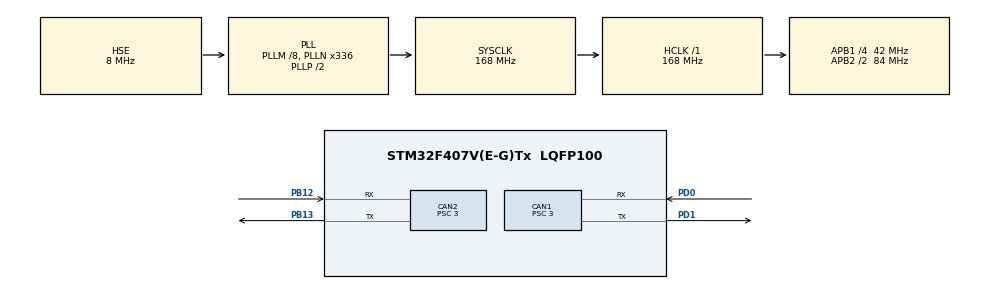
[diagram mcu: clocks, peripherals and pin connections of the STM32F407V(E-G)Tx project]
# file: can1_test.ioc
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CAN1.BS1=CAN_BS1_9TQ
CAN1.BS2=CAN_BS2_4TQ
CAN1.CalculateBaudRate=1000000
CAN1.CalculateTimeBit=999.99
CAN1.CalculateTimeQuantum=71.42857142857143
CAN1.Prescaler=3
CAN1.TXFP=ENABLE
CAN2.BS1=CAN_BS1_9TQ
CAN2.BS2=CAN_BS2_4TQ
CAN2.CalculateBaudRate=1000000
CAN2.CalculateTimeBit=999.99
CAN2.CalculateTimeQuantum=71.42857142857143
CAN2.Prescaler=3
CAN2.TXFP=ENABLE
FREERTOS.BinarySemaphores01=myBinarySem01,Dynamic,NULL;myBinarySem02,Dynamic,NULL
FREERTOS.Tasks01=defaultTask,0,128,StartDefaultTask,Default,NULL,Dynamic,NULL,NULL;pid_Task,0,128,PID_Task,Default,NULL,Dynamic,NULL,NULL
FREERTOS.Timers01=myTimer01,Callback01,osTimerPeriodic,Default,NULL,Dynamic,NULL
FREERTOS.configTIMER_TASK_PRIORITY=3
FREERTOS.configUSE_TIMERS=1
Mcu.Family=STM32F4
Mcu.Name=STM32F407V(E-G)Tx
Mcu.Package=LQFP100
NVIC.CAN1_RX0_IRQn=true\:5\:0\:false\:false\:true\:true\:true\:true
NVIC.CAN1_TX_IRQn=true\:5\:0\:false\:false\:true\:true\:true\:true
NVIC.CAN2_RX0_IRQn=true\:5\:0\:false\:false\:true\:true\:true\:true
NVIC.CAN2_TX_IRQn=true\:5\:0\:false\:false\:true\:true\:true\:true
NVIC.PriorityGroup=NVIC_PRIORITYGROUP_4
NVIC.TIM6_DAC_IRQn=true\:15\:0\:false\:false\:true\:false\:false\:true
NVIC.TimeBase=TIM6_DAC_IRQn
NVIC.TimeBaseIP=TIM6
NVIC.WWDG_IRQn=true\:5\:0\:false\:false\:true\:true\:true\:true
PA13.Mode=Serial_Wire
PA13.Signal=SYS_JTMS-SWDIO
PA14.Mode=Serial_Wire
PA14.Signal=SYS_JTCK-SWCLK
PB12.Mode=CAN_Activate
PB12.Signal=CAN2_RX
PB13.Mode=CAN_Activate
PB13.Signal=CAN2_TX
PD0.Mode=CAN_Activate
PD0.Signal=CAN1_RX
PD1.Mode=CAN_Activate
PD1.Signal=CAN1_TX
PH0-OSC_IN.Mode=HSE-External-Oscillator
PH0-OSC_IN.Signal=RCC_OSC_IN
PH1-OSC_OUT.Mode=HSE-External-Oscillator
PH1-OSC_OUT.Signal=RCC_OSC_OUT
ProjectManager.HeapSize=0x200
ProjectManager.StackSize=0x400
ProjectManager.TargetToolchain=MDK-ARM V5.32
RCC.48MHZClocksFreq_Value=84000000
RCC.AHBFreq_Value=168000000
RCC.APB1CLKDivider=RCC_HCLK_DIV4
RCC.APB1Freq_Value=42000000
RCC.APB1TimFreq_Value=84000000
RCC.APB2CLKDivider=RCC_HCLK_DIV2
RCC.APB2Freq_Value=84000000
RCC.APB2TimFreq_Value=168000000
RCC.CortexFreq_Value=168000000
RCC.HCLKFreq_Value=168000000
RCC.HSE_VALUE=8000000
RCC.HSI_VALUE=16000000
RCC.LSE_VALUE=32768
RCC.PLLM=8
RCC.PLLN=336
RCC.PLLSourceVirtual=RCC_PLLSOURCE_HSE
RCC.SYSCLKFreq_VALUE=168000000
RCC.SYSCLKSource=RCC_SYSCLKSOURCE_PLLCLK
RCC.VCOOutputFreq_Value=336000000
VP_FREERTOS_VS_CMSIS_V1.Mode=CMSIS_V1
VP_SYS_VS_tim6.Mode=TIM6
VP_WWDG_VS_WWDG.Mode=WWDG_Activate
WWDG.Counter=127
WWDG.EWIMode=WWDG_EWI_ENABLE
WWDG.Prescaler=WWDG_PRESCALER_2
board=custom

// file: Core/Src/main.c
/* USER CODE BEGIN Header */
/**
  ******************************************************************************
  * @file           : main.c
  * @brief          : Main program body
  ******************************************************************************
  * @attention
  *
  * <h2><center>&copy; Copyright (c) 2021 STMicroelectronics.
  * All rights reserved.</center></h2>
  *
  * This software component is licensed by ST under BSD 3-Clause license,
  * the "License"; You may not use this file except in compliance with the
  * License. You may obtain a copy of the License at:
  *                        opensource.org/licenses/BSD-3-Clause
  *
  ******************************************************************************
  */
/* USER CODE END Header */
#include "main.h"
#include "cmsis_os.h"
#include "can.h"
#include "wwdg.h"
#include "gpio.h"

/* USER CODE BEGIN Includes */
#include "global_variate.h"
/* USER CODE END Includes */

void SystemClock_Config(void);
void MX_FREERTOS_Init(void);

int main(void)
{

  /* MCU Configuration--------------------------------------------------------*/

  /* Reset of all peripherals, Initializes the Flash interface and the Systick. */
  HAL_Init();

  /* Configure the system clock */
  SystemClock_Config();

  /* Initialize all configured peripherals */
  MX_GPIO_Init();
  MX_CAN1_Init();
  MX_CAN2_Init();
  MX_WWDG_Init();

  /* Call init function for freertos objects (in freertos.c) */
  MX_FREERTOS_Init();
  /* Start scheduler */
  osKernelStart();

  /* We should never get here as control is now taken by the scheduler */
  /* Infinite loop */
  while (1)
  {

  }
}

void SystemClock_Config(void)
{
  RCC_OscInitTypeDef RCC_OscInitStruct = {0};
  RCC_ClkInitTypeDef RCC_ClkInitStruct = {0};

  /** Configure the main internal regulator output voltage
  */
  __HAL_RCC_PWR_CLK_ENABLE();
  __HAL_PWR_VOLTAGESCALING_CONFIG(PWR_REGULATOR_VOLTAGE_SCALE1);
  /** Initializes the RCC Oscillators according to the specified parameters
  * in the RCC_OscInitTypeDef structure.
  */
  RCC_OscInitStruct.OscillatorType = RCC_OSCILLATORTYPE_HSE;
  RCC_OscInitStruct.HSEState = RCC_HSE_ON;
  RCC_OscInitStruct.PLL.PLLState = RCC_PLL_ON;
  RCC_OscInitStruct.PLL.PLLSource = RCC_PLLSOURCE_HSE;
  RCC_OscInitStruct.PLL.PLLM = 8;
  RCC_OscInitStruct.PLL.PLLN = 336;
  RCC_OscInitStruct.PLL.PLLP = RCC_PLLP_DIV2;
  RCC_OscInitStruct.PLL.PLLQ = 4;
  if (HAL_RCC_OscConfig(&RCC_OscInitStruct) != HAL_OK)
  {
    Error_Handler();
  }
  /** Initializes the CPU, AHB and APB buses clocks
  */
  RCC_ClkInitStruct.ClockType = RCC_CLOCKTYPE_HCLK|RCC_CLOCKTYPE_SYSCLK
                              |RCC_CLOCKTYPE_PCLK1|RCC_CLOCKTYPE_PCLK2;
  RCC_ClkInitStruct.SYSCLKSource = RCC_SYSCLKSOURCE_PLLCLK;
  RCC_ClkInitStruct.AHBCLKDivider = RCC_SYSCLK_DIV1;
  RCC_ClkInitStruct.APB1CLKDivider = RCC_HCLK_DIV4;
  RCC_ClkInitStruct.APB2CLKDivider = RCC_HCLK_DIV2;

  if (HAL_RCC_ClockConfig(&RCC_ClkInitStruct, FLASH_LATENCY_5) != HAL_OK)
  {
    Error_Handler();
  }
}

void HAL_TIM_PeriodElapsedCallback(TIM_HandleTypeDef *htim)
{
  if (htim->Instance == TIM6) {
    HAL_IncTick();
  }
}

void Error_Handler(void)
{
  __disable_irq();
  while (1)
  {
  }
}

/************************ (C) COPYRIGHT STMicroelectronics *****END OF FILE****/

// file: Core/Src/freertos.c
/* USER CODE BEGIN Header */
/**
  ******************************************************************************
  * File Name          : freertos.c
  * Description        : Code for freertos applications
  ******************************************************************************
  * @attention
  *
  * <h2><center>&copy; Copyright (c) 2021 STMicroelectronics.
  * All rights reserved.</center></h2>
  *
  * This software component is licensed by ST under Ultimate Liberty license
  * SLA0044, the "License"; You may not use this file except in compliance with
  * the License. You may obtain a copy of the License at:
  *                             www.st.com/SLA0044
  *
  ******************************************************************************
  */
/* USER CODE END Header */

#include "FreeRTOS.h"
#include "task.h"
#include "main.h"
#include "cmsis_os.h"

/* USER CODE BEGIN Includes */

#include "can.h"
#include "PID.h"
#include "global_variate.h"
#include "motor_control.h"

/* USER CODE END Includes */

/* USER CODE BEGIN PD */

//extern float target_pitch_angle;
//extern float target_yaw_angle;

/* USER CODE END PD */

osThreadId defaultTaskHandle;
osThreadId pid_TaskHandle;
osTimerId myTimer01Handle;
osSemaphoreId myBinarySem01Handle;
osSemaphoreId myBinarySem02Handle;

void StartDefaultTask(void const * argument);
void PID_Task(void const * argument);
void Callback01(void const * argument);

void MX_FREERTOS_Init(void); /* (MISRA C 2004 rule 8.1) */

/* GetIdleTaskMemory prototype (linked to static allocation support) */
void vApplicationGetIdleTaskMemory( StaticTask_t **ppxIdleTaskTCBBuffer, StackType_t **ppxIdleTaskStackBuffer, uint32_t *pulIdleTaskStackSize );

/* GetTimerTaskMemory prototype (linked to static allocation support) */
void vApplicationGetTimerTaskMemory( StaticTask_t **ppxTimerTaskTCBBuffer, StackType_t **ppxTimerTaskStackBuffer, uint32_t *pulTimerTaskStackSize );

/* USER CODE BEGIN GET_IDLE_TASK_MEMORY */
static StaticTask_t xIdleTaskTCBBuffer;
static StackType_t xIdleStack[configMINIMAL_STACK_SIZE];

void vApplicationGetIdleTaskMemory( StaticTask_t **ppxIdleTaskTCBBuffer, StackType_t **ppxIdleTaskStackBuffer, uint32_t *pulIdleTaskStackSize )
{
  *ppxIdleTaskTCBBuffer = &xIdleTaskTCBBuffer;
  *ppxIdleTaskStackBuffer = &xIdleStack[0];
  *pulIdleTaskStackSize = configMINIMAL_STACK_SIZE;
  /* place for user code */
}
/* USER CODE END GET_IDLE_TASK_MEMORY */

/* USER CODE BEGIN GET_TIMER_TASK_MEMORY */
static StaticTask_t xTimerTaskTCBBuffer;
static StackType_t xTimerStack[configTIMER_TASK_STACK_DEPTH];

void vApplicationGetTimerTaskMemory( StaticTask_t **ppxTimerTaskTCBBuffer, StackType_t **ppxTimerTaskStackBuffer, uint32_t *pulTimerTaskStackSize )
{
  *ppxTimerTaskTCBBuffer = &xTimerTaskTCBBuffer;
  *ppxTimerTaskStackBuffer = &xTimerStack[0];
  *pulTimerTaskStackSize = configTIMER_TASK_STACK_DEPTH;
  /* place for user code */
}
/* USER CODE END GET_TIMER_TASK_MEMORY */

void MX_FREERTOS_Init(void) {

  /* Create the semaphores(s) */
  /* definition and creation of myBinarySem01 */
  osSemaphoreDef(myBinarySem01);
  myBinarySem01Handle = osSemaphoreCreate(osSemaphore(myBinarySem01), 1);

  /* definition and creation of myBinarySem02 */
  osSemaphoreDef(myBinarySem02);
  myBinarySem02Handle = osSemaphoreCreate(osSemaphore(myBinarySem02), 1);

  /* Create the timer(s) */
  /* definition and creation of myTimer01 */
  osTimerDef(myTimer01, Callback01);
  myTimer01Handle = osTimerCreate(osTimer(myTimer01), osTimerPeriodic, NULL);

  /* Create the thread(s) */
  /* definition and creation of defaultTask */
  osThreadDef(defaultTask, StartDefaultTask, osPriorityNormal, 0, 128);
  defaultTaskHandle = osThreadCreate(osThread(defaultTask), NULL);

  /* definition and creation of pid_Task */
  osThreadDef(pid_Task, PID_Task, osPriorityNormal, 0, 128);
  pid_TaskHandle = osThreadCreate(osThread(pid_Task), NULL);

}

void StartDefaultTask(void const * argument)
{
  for(;;)
  {
    osDelay(1);
  }
}

void PID_Task(void const * argument)
{
  /* USER CODE BEGIN PID_Task */
  /* Infinite loop */
  for(;;)
  {
		Angle_pitch(target_pitch_angle);
		Angle_yaw(target_yaw_angle);
		CAN1_SendCurrent(0x1FF,PID_pitch_6020Vel.fpU,0,0,0);
		CAN2_SendCurrent(0x1FF,PID_yaw_6020Vel.fpU,0,0,0);
    osDelay(1);
  }
  /* USER CODE END PID_Task */
}

/* Callback01 function */
void Callback01(void const * argument)
{
}

/************************ (C) COPYRIGHT STMicroelectronics *****END OF FILE****/
